# CY8C3245AXI_158 register map
File version: 0.1
CY8C32
Registers are 8-bit, read-write, no defined reset value unless marked. A register's access mark holds for its fields unless they carry their own. Offsets are from the block's base; lines under a group give offsets from that group; [hi:lo] are bit positions; {n}, {i} and the like mark numbered series; 'fields as' and 'values as' point back to an identical list; <NAME> marks a mode.

## Memory map
0x00006400 QuadDec_R size 0x64
0x00006400 QuadDec_R_Cnt16 size 0x92
0x00006406 QuadDec_L size 0x60
0x00006406 QuadDec_L_Cnt16 size 0x191
0x00006422 PWM_1 size 0x71
0x00006428 LIN_1_UART size 0x142 — UART
0x0000642A LIN_1 size 0x64
0x0000642E PWM_2 size 0x71
0x0000644F UART_1 size 0x21 — UART

## QuadDec_R
Base 0x00006400
0x00 QuadDec_R_Cnt16_COUNTER 16-bit — Counter value
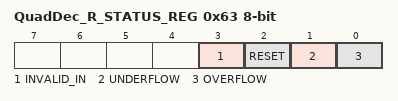
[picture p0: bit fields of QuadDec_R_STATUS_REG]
0x63 QuadDec_R_STATUS_REG — Quadrature Decoder Status Register
  [3] INVALID_IN ro — Invalid state transition on the A and B inputs
  [2] RESET ro — Counter Reset due index
  [1] UNDERFLOW ro — Counter underflow
  [0] OVERFLOW ro — Counter overflow

## QuadDec_R_Cnt16
Base 0x00006400
0x00 QuadDec_R_Cnt16_COUNTER 16-bit — UDB.A0 - Current Counter Value
0x20 QuadDec_R_Cnt16_PERIOD 16-bit — UDB.D0 - Assigned Period
0x30 QuadDec_R_Cnt16_COMPARE 16-bit — UDB.D1 - Assigned Compare Value
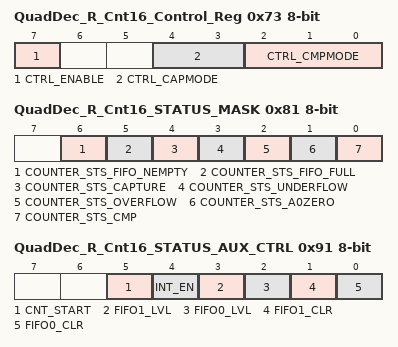
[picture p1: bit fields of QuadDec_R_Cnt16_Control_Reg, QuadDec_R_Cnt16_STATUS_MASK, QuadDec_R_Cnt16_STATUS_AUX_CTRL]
0x73 QuadDec_R_Cnt16_Control_Reg — UDB Control Register - Assigned Control Register Value
  [7] CTRL_ENABLE — Enable Counter
  [4:3] CTRL_CAPMODE — Capture mode
  [2:0] CTRL_CMPMODE — Compare mode
0x81 QuadDec_R_Cnt16_STATUS_MASK — UDB Status bits Interrupt Mask Enable Register
  [6] COUNTER_STS_FIFO_NEMPTY — FIFO Not Empty Status
  [5] COUNTER_STS_FIFO_FULL — FIFO Full Status
  [4] COUNTER_STS_CAPTURE — Capture Status
  [3] COUNTER_STS_UNDERFLOW — Underflow status
  [2] COUNTER_STS_OVERFLOW — Overflow status
  [1] COUNTER_STS_A0ZERO — A0 Zero ouput status
  [0] COUNTER_STS_CMP — Compare output status
0x91 QuadDec_R_Cnt16_STATUS_AUX_CTRL — UDB Auxilliary Control Register
  [5] CNT_START — FIFO0 clear
    0=E_CNT_START0 (Disable counter); 1=E_CNT_START1 (Enable counter)
  [4] INT_EN
    0=E_INT_EN0 (Interrupt disabled); 1=E_INT_EN1 (Interrupt enabled)
  [3] FIFO1_LVL — FIFO level
    0=E_FIFO_LVL_0 (FIFO LVL: input mode: FIFO not full; output mode: FIFO not empty); 1=E_FIFO_LVL_1 (FIFO LVL: input mode: FIFO at least 1/2 empty; output mode: FIFO at least 1/2 full)
  [2] FIFO0_LVL — FIFO level
    values as FIFO1_LVL
  [1] FIFO1_CLR — FIFO1 clear
    0=E_FIFO_CLR_0 (Normal FIFO operation); 1=E_FIFO_CLR_1 (Clear FIFO state)
  [0] FIFO0_CLR — FIFO0 clear
    values as FIFO1_CLR

## UART_1 — UART
Base 0x0000644F
0x00 TX_UART_1_TX_DATA — TX Data Register
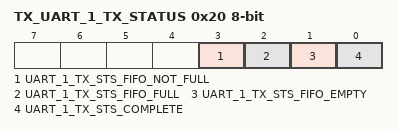
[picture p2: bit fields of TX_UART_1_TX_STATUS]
0x20 TX_UART_1_TX_STATUS — TX status register
  [3] UART_1_TX_STS_FIFO_NOT_FULL ro, [2] UART_1_TX_STS_FIFO_FULL ro, [1] UART_1_TX_STS_FIFO_EMPTY ro, [0] UART_1_TX_STS_COMPLETE ro

## QuadDec_L
Base 0x00006406
0x00 QuadDec_L_Cnt16_COUNTER 16-bit — Counter value
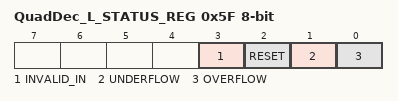
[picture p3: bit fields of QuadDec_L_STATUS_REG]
0x5F QuadDec_L_STATUS_REG — Quadrature Decoder Status Register
  [3] INVALID_IN ro — Invalid state transition on the A and B inputs
  [2] RESET ro — Counter Reset due index
  [1] UNDERFLOW ro — Counter underflow
  [0] OVERFLOW ro — Counter overflow

## QuadDec_L_Cnt16
Base 0x00006406
0x00 QuadDec_L_Cnt16_COUNTER 16-bit — UDB.A0 - Current Counter Value
0x20 QuadDec_L_Cnt16_PERIOD 16-bit — UDB.D0 - Assigned Period
0x30 QuadDec_L_Cnt16_COMPARE 16-bit — UDB.D1 - Assigned Compare Value
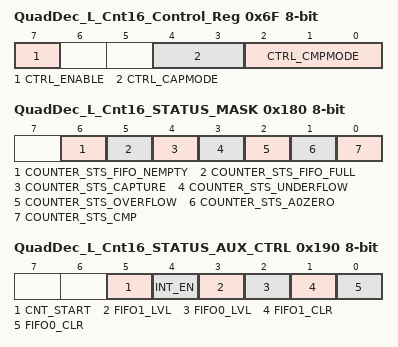
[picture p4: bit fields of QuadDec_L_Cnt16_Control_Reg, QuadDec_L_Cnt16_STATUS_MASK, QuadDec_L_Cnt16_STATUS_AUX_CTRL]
0x6F QuadDec_L_Cnt16_Control_Reg — UDB Control Register - Assigned Control Register Value
  [7] CTRL_ENABLE — Enable Counter
  [4:3] CTRL_CAPMODE — Capture mode
  [2:0] CTRL_CMPMODE — Compare mode
0x180 QuadDec_L_Cnt16_STATUS_MASK — UDB Status bits Interrupt Mask Enable Register
  fields as QuadDec_R_Cnt16.QuadDec_R_Cnt16_STATUS_MASK
0x190 QuadDec_L_Cnt16_STATUS_AUX_CTRL — UDB Auxilliary Control Register
  fields as QuadDec_R_Cnt16.QuadDec_R_Cnt16_STATUS_AUX_CTRL

## PWM_1
Base 0x00006422
0x00 PWM_1__COMPARE1 — UDB.D0 - Assigned Compare1 Value
0x10 PWM_1__COMPARE2 — UDB.D1 - Assigned Compare2 Value
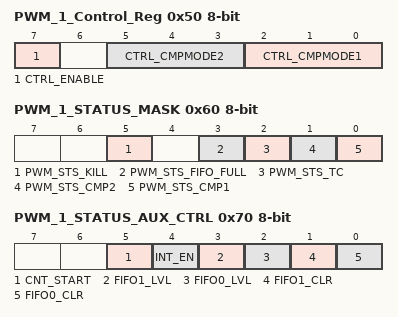
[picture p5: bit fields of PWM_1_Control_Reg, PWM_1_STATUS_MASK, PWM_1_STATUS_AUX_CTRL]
0x50 PWM_1_Control_Reg — UDB Control Register - Assigned Control Register Value
  [7] CTRL_ENABLE — Enable the PWM
  [5:3] CTRL_CMPMODE2 — Compare mode 2
  [2:0] CTRL_CMPMODE1 — Compare mode 1
0x60 PWM_1_STATUS_MASK — UDB Status bits Interrupt Mask Enable Register
  [5] PWM_STS_KILL ro — Enables the Interrupt on Kill
  [3] PWM_STS_FIFO_FULL ro — FIFO Full Status Mask
  [2] PWM_STS_TC ro — Enables the Interrupt on Terminal Count
  [1] PWM_STS_CMP2 ro — Enables the Interrupt on Compare 2
  [0] PWM_STS_CMP1 ro — Enables the Interrupt on Compare 1
0x70 PWM_1_STATUS_AUX_CTRL — UDB Auxilliary Control Register
  fields as QuadDec_R_Cnt16.QuadDec_R_Cnt16_STATUS_AUX_CTRL

## PWM_2
Base 0x0000642E
Registers as PWM_1 (with PWM_1 read as PWM_2).

## LIN_1
Base 0x0000642A
0x00 INACT_INACTIVITY_DIV0_REG — Bus Inactivity Divider 0 Register
  [7:0] LIN_1_INACTIVITY_DIV0 — ((Baud Rate * 16 (oversampling) / 10 (100 ms)) / 256) - 1
0x03 BREAK_THRESHOLD_REG — Break Threshold Register
  [7:0] LIN_1_BREAK_THRESHOLD — Break threshold detection value assuming 16x oversampling
0x10 INACT_INACTIVITY_DIV1_REG — Bus Inactivity Divider 1 Register
  [7:0] LIN_1_INACTIVITY_DIV1 — (Baud Rate * 16 (oversampling) / 10 (100 ms)) % 256
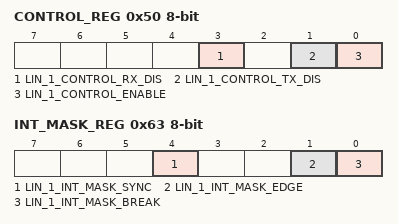
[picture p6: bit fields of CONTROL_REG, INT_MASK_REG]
0x50 CONTROL_REG — Control Register
  [3] LIN_1_CONTROL_RX_DIS — Disconnect RX from LIN bus
  [1] LIN_1_CONTROL_TX_DIS — Force TX pin low
  [0] LIN_1_CONTROL_ENABLE — Enable base LIN operation
0x63 INT_MASK_REG — Status Mask Register
  [4] LIN_1_INT_MASK_SYNC — Sync field detected mask
  [1] LIN_1_INT_MASK_EDGE — Edge detected mask
  [0] LIN_1_INT_MASK_BREAK — Break field threshold detected mask

## LIN_1_UART — UART
Base 0x00006428
0x00 RX_LIN_1_UART_RX_ADDRESS1 — RX Address1 Register
0x10 RX_LIN_1_UART_RX_ADDRESS2 — RX Address2 Register
0x20 RX_LIN_1_UART_RX_DATA — RX Data Register
0x120 TX_LIN_1_UART_TX_DATA — TX Data Register
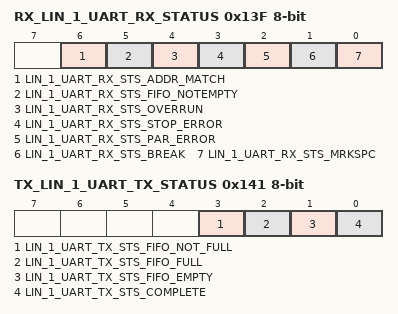
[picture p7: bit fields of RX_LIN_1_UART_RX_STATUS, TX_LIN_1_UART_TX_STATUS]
0x13F RX_LIN_1_UART_RX_STATUS — RX status register
  [6] LIN_1_UART_RX_STS_ADDR_MATCH ro, [5] LIN_1_UART_RX_STS_FIFO_NOTEMPTY ro, [4] LIN_1_UART_RX_STS_OVERRUN ro, [3] LIN_1_UART_RX_STS_STOP_ERROR ro, [2] LIN_1_UART_RX_STS_PAR_ERROR ro, [1] LIN_1_UART_RX_STS_BREAK ro, [0] LIN_1_UART_RX_STS_MRKSPC ro
0x141 TX_LIN_1_UART_TX_STATUS — TX status register
  [3] LIN_1_UART_TX_STS_FIFO_NOT_FULL ro, [2] LIN_1_UART_TX_STS_FIFO_FULL ro, [1] LIN_1_UART_TX_STS_FIFO_EMPTY ro, [0] LIN_1_UART_TX_STS_COMPLETE ro
